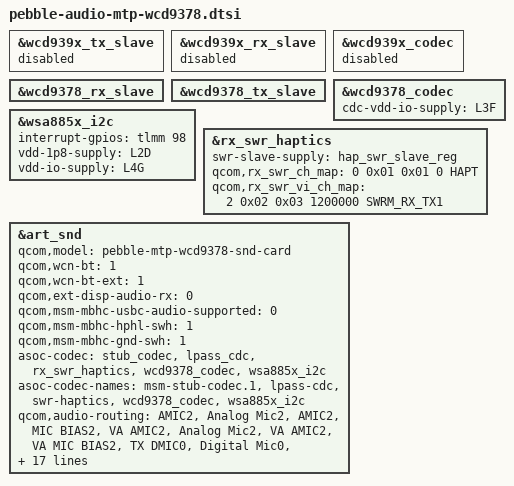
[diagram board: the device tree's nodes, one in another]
/*
 * Copyright (c) Qualcomm Technologies, Inc. and/or its subsidiaries.
 * SPDX-License-Identifier: BSD-3-Clause-Clear
*/

/dts-v1/;
/plugin/;

#include "art-audio-mtp.dtsi"

&wcd939x_tx_slave {
	status = "disabled";
};

&wcd939x_rx_slave {
	status = "disabled";
};

&wcd939x_codec {
	status = "disabled";
};

&wcd9378_rx_slave {
	status = "okay";
};

&wcd9378_tx_slave {
	status = "okay";
};

&wcd9378_codec {
	status = "okay";
	cdc-vdd-io-supply = <&L3F>;
};

&wsa885x_i2c {
	interrupt-gpios = <&tlmm 98 GPIO_ACTIVE_HIGH>;
	vdd-1p8-supply = <&L2D>;
	vdd-io-supply = <&L4G>;
};

&rx_swr_haptics {
	status = "okay";
	swr-slave-supply = <&hap_swr_slave_reg>;
	qcom,rx_swr_ch_map = <0 0x01 0x01 0 HAPT>;
	qcom,rx_swr_vi_ch_map = <2 0x02 0x03 1200000 SWRM_RX_TX1>;
};

&art_snd {
	qcom,model = "pebble-mtp-wcd9378-snd-card";
	qcom,wcn-bt = <1>;
	qcom,wcn-bt-ext = <1>;
	qcom,ext-disp-audio-rx = <0>;
	qcom,msm-mbhc-usbc-audio-supported = <0>;
	qcom,msm-mbhc-hphl-swh = <1>;
	qcom,msm-mbhc-gnd-swh = <1>;
	/delete-property/ wcd939x-i2c-handle;
	asoc-codec  = <&stub_codec>, <&lpass_cdc>,
		      <&rx_swr_haptics>, <&wcd9378_codec>, <&wsa885x_i2c>;
	asoc-codec-names = "msm-stub-codec.1", "lpass-cdc",
			"swr-haptics", "wcd9378_codec", "wsa885x_i2c";
	qcom,audio-routing =
			"AMIC2", "Analog Mic2",
			"AMIC2", "MIC BIAS2",
			"VA AMIC2", "Analog Mic2",
			"VA AMIC2", "VA MIC BIAS2",
			"TX DMIC0", "Digital Mic0",
			"TX DMIC0", "MIC BIAS1",
			"TX DMIC1", "Digital Mic1",
			"TX DMIC1", "MIC BIAS1",
			"TX DMIC2", "Digital Mic2",
			"TX DMIC2", "MIC BIAS3",
			"TX DMIC3", "Digital Mic3",
			"TX DMIC3", "MIC BIAS3",
			"IN1_HPHL", "HPHL_OUT",
			"IN2_HPHR", "HPHR_OUT",
			"IN3_AUX", "AUX_OUT",
			"HAP_IN", "PCM_OUT",
			"RX_TX DEC0_INP", "TX DEC0 MUX",
			"RX_TX DEC1_INP", "TX DEC1 MUX",
			"RX_TX DEC2_INP", "TX DEC2 MUX",
			"RX_TX DEC3_INP", "TX DEC3 MUX",
			"VA SWR_INPUT", "VA_SWR_CLK",
			"VA_AIF1 CAP", "VA_SWR_CLK",
			"VA_AIF2 CAP", "VA_SWR_CLK",
			"VA_AIF3 CAP", "VA_SWR_CLK",
			"VA DMIC0", "Digital Mic0",
			"VA DMIC1", "Digital Mic1",
			"VA DMIC2", "Digital Mic2",
			"VA DMIC3", "Digital Mic3",
			"VA DMIC0", "VA MIC BIAS1",
			"VA DMIC1", "VA MIC BIAS1",
			"VA DMIC2", "VA MIC BIAS3",
			"VA DMIC3", "VA MIC BIAS3";
};
